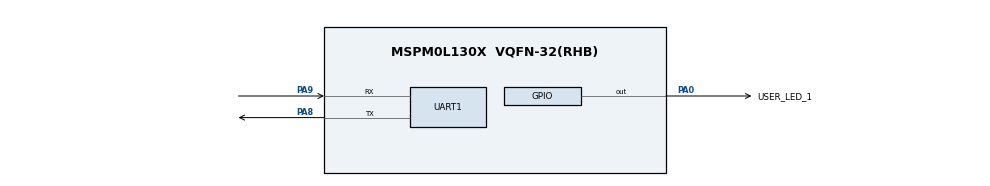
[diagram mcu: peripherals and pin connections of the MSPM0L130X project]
// @cliArgs --device "MSPM0L130X" --package "VQFN-32(RHB)" --part "Default"
// @cliArgs --board /ti/boards/LP_MSPM0L1306 --rtos nortos

/**
 * Import the modules used in this configuration.
 */
const Board  = scripting.addModule("/ti/driverlib/Board");
const GPIO   = scripting.addModule("/ti/driverlib/GPIO", {}, false);
const GPIO1  = GPIO.addInstance();
const SYSCTL = scripting.addModule("/ti/driverlib/SYSCTL");
const UART   = scripting.addModule("/ti/driverlib/UART", {}, false);
const UART1  = UART.addInstance();

/**
 * Write custom configuration values to the imported modules.
 */

GPIO1.$name                                 = "GPIO_LEDS";
GPIO1.associatedPins[0].assignedPort        = "PORTA";
GPIO1.associatedPins[0].assignedPin         = "0";
GPIO1.associatedPins[0].assignedPortSegment = "Lower";
GPIO1.associatedPins[0].$name               = "USER_LED_1";
GPIO1.associatedPins[0].pin.$assign         = "PA0";


UART1.$name                    = "UART_0";
UART1.enableFIFO               = true;
UART1.enableExtend             = true;
UART1.enableManchester         = true;
UART1.peripheral.rxPin.$assign = "PA9";
UART1.peripheral.txPin.$assign = "PA8";

SYSCTL.clockTreeEn = true;
